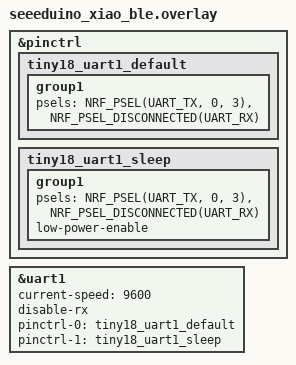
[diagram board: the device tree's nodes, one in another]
#include <zephyr/dt-bindings/pinctrl/nrf-pinctrl.h>

&pinctrl {
    tiny18_uart1_default: tiny18_uart1_default {
        group1 {
            psels = <NRF_PSEL(UART_TX, 0, 3)>,
                    <NRF_PSEL_DISCONNECTED(UART_RX)>;
        };
    };

    tiny18_uart1_sleep: tiny18_uart1_sleep {
        group1 {
            psels = <NRF_PSEL(UART_TX, 0, 3)>,
                    <NRF_PSEL_DISCONNECTED(UART_RX)>;
            low-power-enable;
        };
    };
};

&uart1 {
    status = "okay";
    current-speed = <9600>;
    disable-rx;
    pinctrl-0 = <&tiny18_uart1_default>;
    pinctrl-1 = <&tiny18_uart1_sleep>;
    pinctrl-names = "default", "sleep";
};
